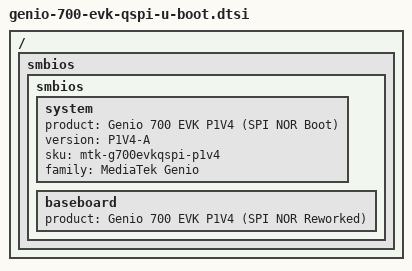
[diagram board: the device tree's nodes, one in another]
// SPDX-License-Identifier: GPL-2.0 OR MIT
/*
 * Copyright (C) 2022 MediaTek Inc.
 * Author: Chris-QJ Chen <chris-qj.chen@mediatek.com>
 *         Pablo Sun <pablo.sun@mediatek.com>
 */

#include "smbios.dtsi"

/ {
	smbios {
		smbios {
			system {
				product = "Genio 700 EVK P1V4 (SPI NOR Boot)";
				version = "P1V4-A";
				sku = "mtk-g700evkqspi-p1v4";
				family = "MediaTek Genio";
			};
			baseboard {
				product = "Genio 700 EVK P1V4 (SPI NOR Reworked)";
			};
		};
	};
};
